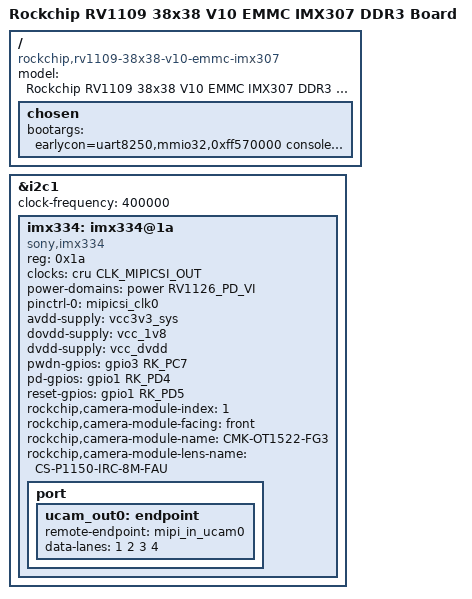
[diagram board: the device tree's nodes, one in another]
// SPDX-License-Identifier: (GPL-2.0+ OR MIT)
/*
 * Copyright (c) 2020 Rockchip Electronics Co., Ltd.
 */

/dts-v1/;

#include "rv11xx-owl-50ipc-v10-emmc.dtsi"

/ {
	model = "Rockchip RV1109 38x38 V10 EMMC IMX307 DDR3 Board";
	compatible = "rockchip,rv1109-38x38-v10-emmc-imx307", "rockchip,rv1126";

	chosen {
		bootargs = "earlycon=uart8250,mmio32,0xff570000 console=ttyFIQ0 root=PARTUUID=614e0000-0000 rootfstype=ext4 rootwait snd_aloop.index=7";
	};

};

&i2c1 {
	status = "okay";
	clock-frequency = <400000>;

	/delete-node/ imx415@1a ;

    imx334: imx334@1a {
        compatible = "sony,imx334";
        reg = <0x1a>;
        clocks = <&cru CLK_MIPICSI_OUT>;
        clock-names = "xvclk";
        power-domains = <&power RV1126_PD_VI>;
        pinctrl-names = "rockchip,camera_default";
        pinctrl-0 = <&mipicsi_clk0>;
        avdd-supply = <&vcc3v3_sys>;
        dovdd-supply = <&vcc_1v8>;
        dvdd-supply = <&vcc_dvdd>;
        pwdn-gpios = <&gpio3 RK_PC7 GPIO_ACTIVE_HIGH>;
        pd-gpios = <&gpio1 RK_PD4 GPIO_ACTIVE_HIGH>;
		reset-gpios = <&gpio1 RK_PD5 GPIO_ACTIVE_HIGH>;
        rockchip,camera-module-index = <1>;
        rockchip,camera-module-facing = "front";
        rockchip,camera-module-name = "CMK-OT1522-FG3";
        rockchip,camera-module-lens-name = "CS-P1150-IRC-8M-FAU";
        port {
			ucam_out0: endpoint {
				remote-endpoint = <&mipi_in_ucam0>;
                data-lanes = <1 2 3 4>;
            };
        };
    };
};

